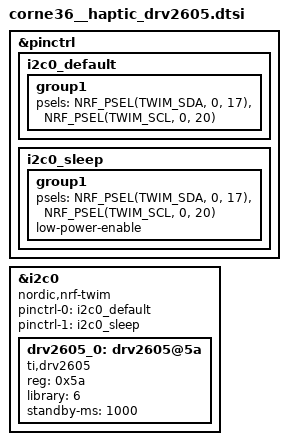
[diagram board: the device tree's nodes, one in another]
/*
 * Copyright (c) 2020 Pete Johanson
 *
 * SPDX-License-Identifier: MIT
 */

&pinctrl {
    i2c0_default: i2c0_default {
        group1 {
            psels = <NRF_PSEL(TWIM_SDA, 0, 17)>,
                    <NRF_PSEL(TWIM_SCL, 0, 20)>;
        };
    };

    i2c0_sleep: i2c0_sleep {
        group1 {
            psels = <NRF_PSEL(TWIM_SDA, 0, 17)>,
                    <NRF_PSEL(TWIM_SCL, 0, 20)>;
            low-power-enable;
        };
    };
};

&i2c0 {
    status = "okay";
    compatible = "nordic,nrf-twim";
    pinctrl-0 = <&i2c0_default>;
    pinctrl-1 = <&i2c0_sleep>;
    pinctrl-names = "default", "sleep";

    drv2605_0: drv2605@5a {
        compatible = "ti,drv2605";
        reg = <0x5a>;
        library = <6>;
        standby-ms = <1000>;
    };
};
